# nrf9120_MLM1 register map
Vendor: Nordic Semiconductor; Series: nrf91; File version: 1
CPU: CM4 r0p1, little endian, MPU, FPU, 3 interrupt priority bits
Registers are 32-bit, read-write, reset 0x0 unless marked. A register's access mark holds for its fields unless they carry their own. Offsets are from the block's base; [hi:lo] are bit positions; {n}, {i} and the like mark numbered series.

## EGU0 — Event Generator Unit
Base 0x40015000; alternate view of SWI0
{0x0+4i} TASKS_TRIGGER[{i}] (i=0..15) wo — Description collection[0]: Trigger 0 for triggering the corresponding TRIGGERED[0] event
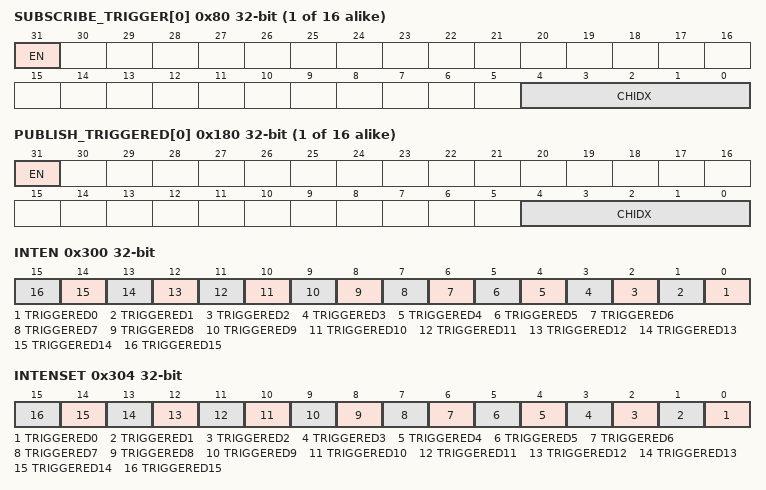
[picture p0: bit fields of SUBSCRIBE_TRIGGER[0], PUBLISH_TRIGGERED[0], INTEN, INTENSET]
{0x80+4i} SUBSCRIBE_TRIGGER[{i}] (i=0..15) — Description collection[0]: Subscribe configuration for TASKS_TRIGGER[0]
  [31] EN
    0=Disabled (Disable subscription); 1=Enabled (Enable subscription)
  [4:0] CHIDX — Channel the TASKS_TRIGGER[0] will subscribe to.
{0x100+4i} EVENTS_TRIGGERED[{i}] (i=0..15) — Description collection[0]: Event number 0 generated by triggering the corresponding TRIGGER[0] task
{0x180+4i} PUBLISH_TRIGGERED[{i}] (i=0..15) — Description collection[0]: Publish configuration for EVENTS_TRIGGERED[0]
  [31] EN
    0=Disabled (Disable publishing); 1=Enabled (Enable publishing)
  [4:0] CHIDX — Channel the EVENTS_TRIGGERED[0] will subscribe to.
0x300 INTEN — Enable or disable interrupt
  [all] fields
    0=Disabled; 1=Enabled
  [n] TRIGGERED{n} (n=0..15) — Enable or disable interrupt for TRIGGERED[{n}] event
0x304 INTENSET — Enable interrupt
  [all] fields
    on read: 0=Disabled (Read: Disabled); 1=Enabled (Read: Enabled) | on write: 1=Set (Enable)
  [n] TRIGGERED{n} (n=0..15) — Write '1' to Enable interrupt for TRIGGERED[{n}] event
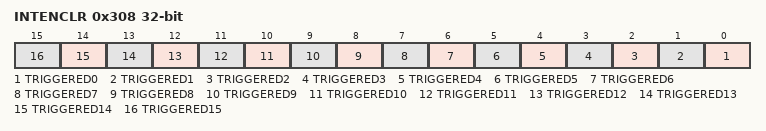
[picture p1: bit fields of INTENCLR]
0x308 INTENCLR — Disable interrupt
  [all] fields
    on read: 0=Disabled (Read: Disabled); 1=Enabled (Read: Enabled) | on write: 1=Clear (Disable)
  [n] TRIGGERED{n} (n=0..15) — Write '1' to Disable interrupt for TRIGGERED[{n}] event

## IPC — Inter Processor Communication
Base 0x40019000
{0x0+4i} TASKS_SEND[{i}] (i=0..7) wo — Description collection[0]: Trigger events on channel enabled in SEND_CNF[0].
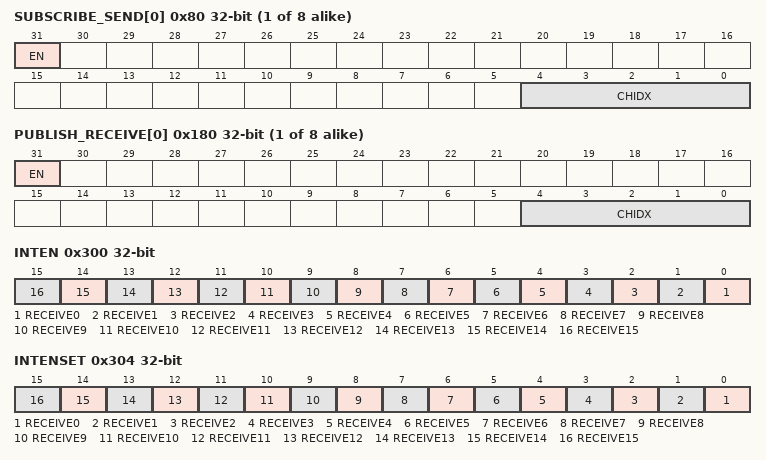
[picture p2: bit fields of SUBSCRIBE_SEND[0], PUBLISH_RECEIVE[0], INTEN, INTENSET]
{0x80+4i} SUBSCRIBE_SEND[{i}] (i=0..7) — Description collection[0]: Subscribe configuration for TASKS_SEND[0]
  [31] EN
    0=Disabled (Disable subscription); 1=Enabled (Enable subscription)
  [4:0] CHIDX — Channel the TASKS_SEND[0] will subscribe to.
{0x100+4i} EVENTS_RECEIVE[{i}] (i=0..7) — Description collection[0]: Event received on one or more of the enabled channels in RECEIVE_CNF[{n}].
{0x180+4i} PUBLISH_RECEIVE[{i}] (i=0..7) — Description collection[0]: Publish configuration for EVENTS_RECEIVE[0]
  [31] EN
    0=Disabled (Disable publishing); 1=Enabled (Enable publishing)
  [4:0] CHIDX — Channel the EVENTS_RECEIVE[0] will subscribe to.
0x300 INTEN — Enable or disable interrupt
  [all] fields
    0=Disabled; 1=Enabled
  [n] RECEIVE{n} (n=0..15) — Enable or disable interrupt for RECEIVE[{n}] event
0x304 INTENSET — Enable interrupt
  [all] fields
    on read: 0=Disabled (Read: Disabled); 1=Enabled (Read: Enabled) | on write: 1=Set (Enable)
  [n] RECEIVE{n} (n=0..15) — Write '1' to Enable interrupt for RECEIVE[{n}] event
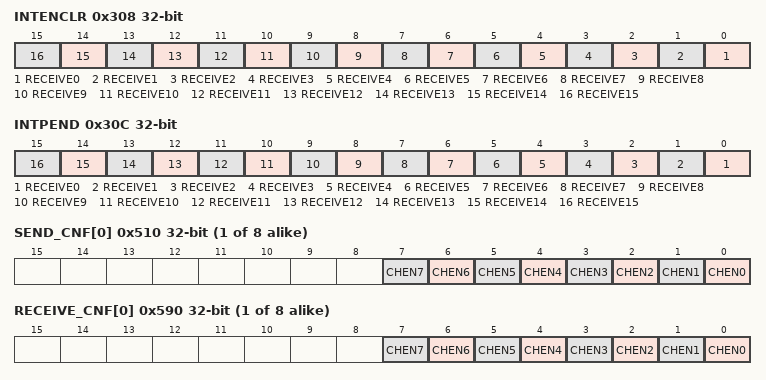
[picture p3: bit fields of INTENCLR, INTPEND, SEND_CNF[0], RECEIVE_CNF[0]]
0x308 INTENCLR — Disable interrupt
  [all] fields
    on read: 0=Disabled (Read: Disabled); 1=Enabled (Read: Enabled) | on write: 1=Clear (Disable)
  [n] RECEIVE{n} (n=0..15) — Write '1' to Disable interrupt for RECEIVE[{n}] event
0x30C INTPEND ro — Pending status of interrupt
  [all] fields
    on read: 0=NotPending (Read: NotPending); 1=Pending (Read: Pending)
  [n] RECEIVE{n} (n=0..15) — Read pending status of interrupt for RECEIVE[{n}] event
{0x510+4i} SEND_CNF[{i}] (i=0..7) — Description collection[0]: Send event configuration for TASKS_SEND[0].
  [all] fields
    0=Disable broadcast; 1=Enable broadcast
  [n] CHEN{n} (n=0..7) — Enable broadcasting on channel {n}.
{0x590+4i} RECEIVE_CNF[{i}] (i=0..7) — Description collection[0]: Receive event configuration for EVENTS_RECEIVE[0].
  [all] fields
    0=Disable events; 1=Enable events
  [n] CHEN{n} (n=0..7) — Enable subscription to channel {n}.
{0x610+4i} GPMEM[{i}] (i=0..1) — Description collection[0]: General purpose memory.
  [31:0] GPMEM — General purpose memory
